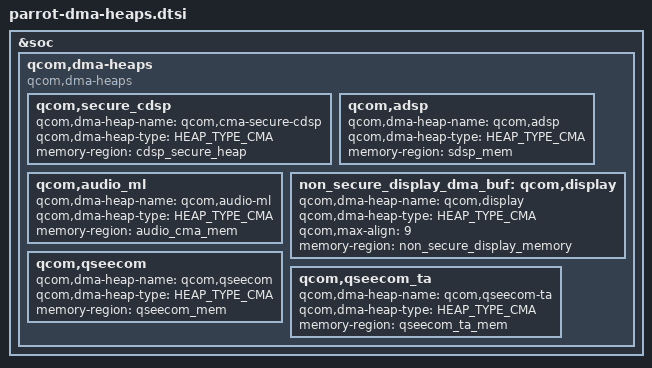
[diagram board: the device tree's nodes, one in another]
#include <dt-bindings/arm/msm/qcom_dma_heap_dt_constants.h>

&soc {
	qcom,dma-heaps {
		compatible = "qcom,dma-heaps";
		qcom,secure_cdsp {
			qcom,dma-heap-name = "qcom,cma-secure-cdsp";
			qcom,dma-heap-type = <HEAP_TYPE_CMA>;
			memory-region = <&cdsp_secure_heap>;
		};

		qcom,adsp {
			qcom,dma-heap-name = "qcom,adsp";
			qcom,dma-heap-type = <HEAP_TYPE_CMA>;
			memory-region = <&sdsp_mem>;
		};

		qcom,audio_ml {
			qcom,dma-heap-name = "qcom,audio-ml";
			qcom,dma-heap-type = <HEAP_TYPE_CMA>;
			memory-region = <&audio_cma_mem>;
		};

		non_secure_display_dma_buf: qcom,display {
			qcom,dma-heap-name = "qcom,display";
			qcom,dma-heap-type = <HEAP_TYPE_CMA>;
			qcom,max-align = <9>;
			memory-region = <&non_secure_display_memory>;
		};

		qcom,qseecom {
			qcom,dma-heap-name = "qcom,qseecom";
			qcom,dma-heap-type = <HEAP_TYPE_CMA>;
			memory-region = <&qseecom_mem>;
		};

		qcom,qseecom_ta {
			qcom,dma-heap-name = "qcom,qseecom-ta";
			qcom,dma-heap-type = <HEAP_TYPE_CMA>;
			memory-region = <&qseecom_ta_mem>;
		};
	};
};
